# HSUSBHOST register map
Vendor: Texas Instruments
Peripheral module from a debugger description file (folder omap4460).
Registers are 32-bit, read-write, reset values left out (the file's numbers can be read two ways) unless marked. A register's access mark holds for its fields unless they carry their own. Offsets are as the file gives them; lines under a group give offsets from that group; [hi:lo] are bit positions; {n}, {i} and the like mark numbered series; 'fields as' and 'values as' point back to an identical list; <NAME> marks a mode.

## HSUSBHOST
0x00 UHH_REVISION ro — USB high-speed host (UHH) revision identifier (X.Y.R) Used by software to track features, bugs, and compatibility
  [31:0] REVISION — IP revision
0x04 UHH_HWINFO ro — Information on host hardware configuration
  [9:0] SAR_CNTX_SIZE — Save-and-restore context size, in 32-bit words; that is, number of 32-bit registers with significant context information, mapped from offset 0x100 upward.
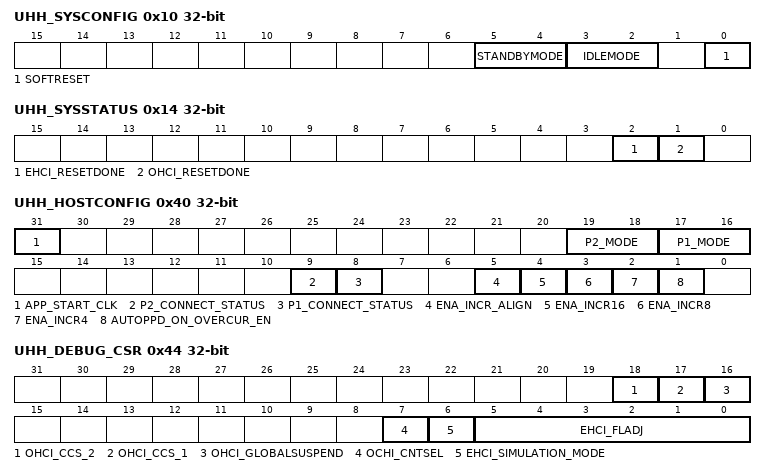
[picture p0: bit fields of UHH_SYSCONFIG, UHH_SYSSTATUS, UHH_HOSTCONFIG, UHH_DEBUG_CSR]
0x10 UHH_SYSCONFIG access per field — OCP standard system configuration register
  [5:4] STANDBYMODE rw — Mstandby/Mwait/[Mwakeup] initiator power-management interface configuration
    0=Force-standby mode. Mstandby asserted unconditionally. Asynchronous (master) wake-up disabled.; 1=No-standby mode. Mstandby never asserted. Asynchronous (master) wakeup disabled.; 2=Smart-standby mode. Mstandby asserted when initiator activity stops. Asynchronous (master) wake-up disabled.
  [3:2] IDLEMODE rw — Sidlereq/Sidleack(1:0)/[Swakeup] target power management interface configuration.
    0=Force-Idle mode. Sidleack asserted after Idlereq assertion. Asynchronous (slave) wake-up disabled.; 1=No-idle mode. Sidleack never asserted. Asynchronous (slave) wakeup disabled.; 2=Smart-idle mode. Sidleack asserted upon Idlereq assertion, after target activity is over. Asynchronous (slave) wake-up disabled.; 3=Smart-idle wake-up mode. Like smart mode with asynchronous (slave) wakeup enabled.
  [0] SOFTRESET rw — Module software reset
    0=SOFTRESET_0_r (No reset pending); 0=SOFTRESET_0_w (No effect); 1=SOFTRESET_1_w (Starts softreset sequence.); 1=SOFTRESET_1_r (Reset (soft or other) is pending.)
0x14 UHH_SYSSTATUS ro — Module-specific system status
  [2] EHCI_RESETDONE — Indicates when the EHCI HS host is out of reset
    0=EHCI_RESETDONE_0_r (Under reset); 1=EHCI_RESETDONE_1_r (Out of reset)
  [1] OHCI_RESETDONE — Indicates when the OHCI FS/LS host is out of reset
    0=OHCI_RESETDONE_0_r (Under reset); 1=OHCI_RESETDONE_1_r (Out of reset)
0x40 UHH_HOSTCONFIG access per field — Static configuration of the USB HS host
  [31] APP_START_CLK rw — When the OHCI clocks are suspended, the system must assert this signal to start the clocks (12 and 48 MHz).This must be deasserted after the clocks are started and before the host is suspended again. . (Host is suspended means HCFS = SUSPEND or all the OHCI ports are suspended.) .
  [19:18] P2_MODE rw — Port 2 interface configuration. Each bit corresponds to an internal 'strap' signal, and output: Bit 0 = ulpi_bypass Bit 1 = hsic_en
    0=To external ULPI PHY, HS only; 1=To UTMI PHY (or ULPI TLL), FS/LS capable; 2=Forbidden; 3=To HSIC digital front-end (DFE), HS only
  [17:16] P1_MODE rw — Port 1 interface configuration. Each bit corresponds to an internal 'strap' signal, and output: Bit 0 = ulpi_bypass Bit 1 = hsic_en
    values as P2_MODE
  [9] P2_CONNECT_STATUS ro — Connection status for port 2
    0=P2_CONNECT_STATUS_0_r (Disconnected); 1=P2_CONNECT_STATUS_1_r (Peripheral connected and active on port)
  [8] P1_CONNECT_STATUS ro — Connection status for port 1
    0=P1_CONNECT_STATUS_0_r (Disconnected); 1=P1_CONNECT_STATUS_1_r (Peripheral connected and active on port)
  [5] ENA_INCR_ALIGN rw — Force alignment of bursts to the respective burst-size boundaries
    0=Disable burst type; 1=Enable burst type
  [4] ENA_INCR16 rw — Control the use of INCR16-type bursts (in AHB sense)
    0=Disable burst type; 1=Enable burst type
  [3] ENA_INCR8 rw — Control the use of INCR8-type bursts (in AHB sense)
    0=Disable burst type; 1=Enable burst type
  [2] ENA_INCR4 rw — Control the use of INCR4-type bursts (in AHB sense)
    0=Disable burst type; 1=Enable burst type
  [1] AUTOPPD_ON_OVERCUR_EN rw — Configure reaction upon port overcurrent condition. This function is not supported at the device level.
    0=Port remains on upon overcurrent; 1=Port is powered down automatically upon overcurrent
0x44 UHH_DEBUG_CSR access per field — Debug control and status for the EHCI, OHCI hosts
  [18] OHCI_CCS_2 ro — Current connect status of port 2
    0=OHCI_CCS_2_0_r (No peripheral connected); 1=OHCI_CCS_2_1_r (Peripheral connected)
  [17] OHCI_CCS_1 ro — Current connect status of port 1
    0=OHCI_CCS_1_0_r (No peripheral connected); 1=OHCI_CCS_1_1_r (Peripheral connected)
  [16] OHCI_GLOBALSUSPEND ro — OHCI global suspend status, asserted 5 ms after the suspend order.
    0=OHCI_GLOBALSUSPEND_0_r (Host is not suspended.); 1=OHCI_GLOBALSUSPEND_1_r (Host is suspended.)
  [7] OCHI_CNTSEL rw — Selection of a shorter '1 ms' counter in OHCI host, to speed up long USB phases such as reset, resume, etc. (used only for simulation)
    0=Functional mode, 1ms = 12,000 × 12 MHz cycles; 1=Simulation mode, 1ms = 7 × 12 MHz cycles = 583 ns
  [6] EHCI_SIMULATION_MODE rw — Sets the PHY to nondriving mode (used only for simulation)
    0=Functional mode; 1=PHY set to nondriving
  [5:0] EHCI_FLADJ rw — EHCI host frame length adjust. Modify only when EHCI Bit FieldUSBSTS.HCHalted = 1 Field value + 59,488 = 60,000 by default = Number of 60-MHz UTMI/ULPI clock cycles per 1 ms USB frame = Number of 480-MHz HS bits per 125 µs HS USB microframe
{0x100+4i} UHH_SAR_CNTX_i_{i} (i=0..383) — Save and restore context array. Array size is indicated in. When in SAR mode, read out to save and write to restore. Do not access when not in SAR mode.
  [31:0] CNTX — Context bits
